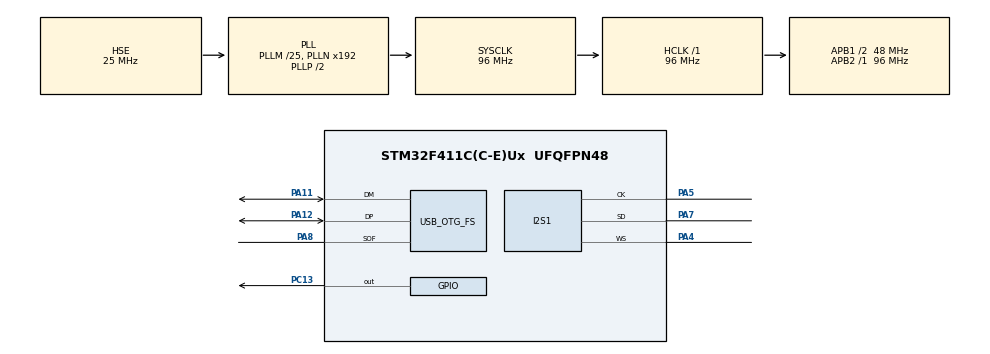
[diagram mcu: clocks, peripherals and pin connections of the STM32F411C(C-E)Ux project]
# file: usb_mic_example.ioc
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Dma.Request0=SPI1_RX
Dma.SPI1_RX.0.Direction=DMA_PERIPH_TO_MEMORY
Dma.SPI1_RX.0.FIFOMode=DMA_FIFOMODE_ENABLE
Dma.SPI1_RX.0.FIFOThreshold=DMA_FIFO_THRESHOLD_FULL
Dma.SPI1_RX.0.Instance=DMA2_Stream0
Dma.SPI1_RX.0.MemBurst=DMA_MBURST_SINGLE
Dma.SPI1_RX.0.MemDataAlignment=DMA_MDATAALIGN_HALFWORD
Dma.SPI1_RX.0.MemInc=DMA_MINC_ENABLE
Dma.SPI1_RX.0.Mode=DMA_CIRCULAR
Dma.SPI1_RX.0.PeriphBurst=DMA_PBURST_SINGLE
Dma.SPI1_RX.0.PeriphDataAlignment=DMA_PDATAALIGN_HALFWORD
Dma.SPI1_RX.0.PeriphInc=DMA_PINC_DISABLE
Dma.SPI1_RX.0.Priority=DMA_PRIORITY_LOW
I2S1.AudioFreq=I2S_AUDIOFREQ_96K
I2S1.DataFormat=I2S_DATAFORMAT_24B
I2S1.ErrorAudioFreq=-2.34 %
I2S1.FullDuplexMode=I2S_FULLDUPLEXMODE_DISABLE
I2S1.Instance=SPI$Index
I2S1.Mode=I2S_MODE_MASTER_RX
I2S1.RealAudioFreq=93.75 KHz
I2S1.VirtualMode=I2S_MODE_MASTER
Mcu.Family=STM32F4
Mcu.Name=STM32F411C(C-E)Ux
Mcu.Package=UFQFPN48
NVIC.DMA2_Stream0_IRQn=true\:0\:0\:false\:false\:true\:false\:true\:true
NVIC.OTG_FS_IRQn=true\:0\:0\:false\:false\:true\:true\:true\:true
NVIC.PriorityGroup=NVIC_PRIORITYGROUP_4
NVIC.SPI1_IRQn=true\:0\:0\:false\:false\:true\:true\:true\:true
NVIC.TIM1_TRG_COM_TIM11_IRQn=true\:15\:0\:false\:false\:true\:false\:true\:true
NVIC.TimeBase=TIM1_TRG_COM_TIM11_IRQn
NVIC.TimeBaseIP=TIM11
PA11.Mode=Device_Only
PA11.Signal=USB_OTG_FS_DM
PA12.Mode=Device_Only
PA12.Signal=USB_OTG_FS_DP
PA13.Mode=Serial_Wire
PA13.Signal=SYS_JTMS-SWDIO
PA14.Mode=Serial_Wire
PA14.Signal=SYS_JTCK-SWCLK
PA4.Mode=Half_Duplex_Master
PA4.Signal=I2S1_WS
PA5.Mode=Half_Duplex_Master
PA5.Signal=I2S1_CK
PA7.Mode=Half_Duplex_Master
PA7.Signal=I2S1_SD
PA8.Mode=Activate_SOF_FS
PA8.Signal=USB_OTG_FS_SOF
PC13-ANTI_TAMP.Signal=GPIO_Output
PH0\ -\ OSC_IN.Mode=HSE-External-Oscillator
PH0\ -\ OSC_IN.Signal=RCC_OSC_IN
PH1\ -\ OSC_OUT.Mode=HSE-External-Oscillator
PH1\ -\ OSC_OUT.Signal=RCC_OSC_OUT
ProjectManager.HeapSize=0x2200
ProjectManager.StackSize=0x4200
ProjectManager.TargetToolchain=Makefile
RCC.48MHZClocksFreq_Value=48000000
RCC.AHBFreq_Value=96000000
RCC.APB1CLKDivider=RCC_HCLK_DIV2
RCC.APB1Freq_Value=48000000
RCC.APB1TimFreq_Value=96000000
RCC.APB2Freq_Value=96000000
RCC.APB2TimFreq_Value=96000000
RCC.CortexFreq_Value=96000000
RCC.HCLKFreq_Value=96000000
RCC.HSE_VALUE=25000000
RCC.HSICalibrationValue=16
RCC.HSI_VALUE=16000000
RCC.LSE_VALUE=32768
RCC.PLLI2SM=25
RCC.PLLM=25
RCC.PWR_Regulator_Voltage_Scale=PWR_REGULATOR_VOLTAGE_SCALE1
RCC.RCC_TIM_PRescaler_Selection=RCC_TIMPRES_ACTIVATED
RCC.SYSCLKFreq_VALUE=96000000
RCC.SYSCLKSource=RCC_SYSCLKSOURCE_PLLCLK
RCC.VCOOutputFreq_Value=192000000
USB_OTG_FS.VirtualMode=Device_Only
VP_SYS_VS_tim11.Mode=TIM11
board=custom

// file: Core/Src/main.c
/* USER CODE BEGIN Header */
/**
  ******************************************************************************
  * @file           : main.c
  * @brief          : Main program body
  ******************************************************************************
  * @attention
  *
  * Copyright (c) 2024 STMicroelectronics.
  * All rights reserved.
  *
  * This software is licensed under terms that can be found in the LICENSE file
  * in the root directory of this software component.
  * If no LICENSE file comes with this software, it is provided AS-IS.
  *
  ******************************************************************************
  */
/* USER CODE END Header */
#include "main.h"
#include "dma.h"
#include "i2s.h"
#include "usb_otg.h"
#include "gpio.h"

void SystemClock_Config(void);
void PeriphCommonClock_Config(void);

int main(void)
{

  /* MCU Configuration--------------------------------------------------------*/

  /* Reset of all peripherals, Initializes the Flash interface and the Systick. */
  HAL_Init();

  /* Configure the system clock */
  SystemClock_Config();

/* Configure the peripherals common clocks */
  PeriphCommonClock_Config();

  /* Initialize all configured peripherals */
  MX_GPIO_Init();
  MX_DMA_Init();
  MX_I2S1_Init();
  // MX_USB_OTG_FS_PCD_Init();
  /* USER CODE BEGIN 2 */
  extern void audio_v1_init(uint8_t busid, uint32_t reg_base);
  audio_v1_init(0, USB_OTG_FS_PERIPH_BASE);
  // USB_OTG_FS_PERIPH_BASE
  extern void audio_test(uint8_t busid);
  audio_test((uint8_t)0);
  /* USER CODE END 2 */

  /* Infinite loop */
  while (1)
  {

  }
}

void SystemClock_Config(void)
{
  RCC_OscInitTypeDef RCC_OscInitStruct = {0};
  RCC_ClkInitTypeDef RCC_ClkInitStruct = {0};

  /** Configure the main internal regulator output voltage
  */
  __HAL_RCC_PWR_CLK_ENABLE();
  __HAL_PWR_VOLTAGESCALING_CONFIG(PWR_REGULATOR_VOLTAGE_SCALE1);

  /** Initializes the RCC Oscillators according to the specified parameters
  * in the RCC_OscInitTypeDef structure.
  */
  RCC_OscInitStruct.OscillatorType = RCC_OSCILLATORTYPE_HSE;
  RCC_OscInitStruct.HSEState = RCC_HSE_ON;
  RCC_OscInitStruct.PLL.PLLState = RCC_PLL_ON;
  RCC_OscInitStruct.PLL.PLLSource = RCC_PLLSOURCE_HSE;
  RCC_OscInitStruct.PLL.PLLM = 25;
  RCC_OscInitStruct.PLL.PLLN = 192;
  RCC_OscInitStruct.PLL.PLLP = RCC_PLLP_DIV2;
  RCC_OscInitStruct.PLL.PLLQ = 4;
  if (HAL_RCC_OscConfig(&RCC_OscInitStruct) != HAL_OK)
  {
    Error_Handler();
  }

  /** Initializes the CPU, AHB and APB buses clocks
  */
  RCC_ClkInitStruct.ClockType = RCC_CLOCKTYPE_HCLK|RCC_CLOCKTYPE_SYSCLK
                              |RCC_CLOCKTYPE_PCLK1|RCC_CLOCKTYPE_PCLK2;
  RCC_ClkInitStruct.SYSCLKSource = RCC_SYSCLKSOURCE_PLLCLK;
  RCC_ClkInitStruct.AHBCLKDivider = RCC_SYSCLK_DIV1;
  RCC_ClkInitStruct.APB1CLKDivider = RCC_HCLK_DIV2;
  RCC_ClkInitStruct.APB2CLKDivider = RCC_HCLK_DIV1;

  if (HAL_RCC_ClockConfig(&RCC_ClkInitStruct, FLASH_LATENCY_3) != HAL_OK)
  {
    Error_Handler();
  }
}

void PeriphCommonClock_Config(void)
{
  RCC_PeriphCLKInitTypeDef PeriphClkInitStruct = {0};

  /** Initializes the peripherals clock
  */
  PeriphClkInitStruct.PeriphClockSelection = RCC_PERIPHCLK_TIM;
  PeriphClkInitStruct.TIMPresSelection = RCC_TIMPRES_ACTIVATED;
  if (HAL_RCCEx_PeriphCLKConfig(&PeriphClkInitStruct) != HAL_OK)
  {
    Error_Handler();
  }
}

void HAL_TIM_PeriodElapsedCallback(TIM_HandleTypeDef *htim)
{
  if (htim->Instance == TIM11) {
    HAL_IncTick();
  }
}

void Error_Handler(void)
{
  __disable_irq();
  while (1)
  {
  }
}
